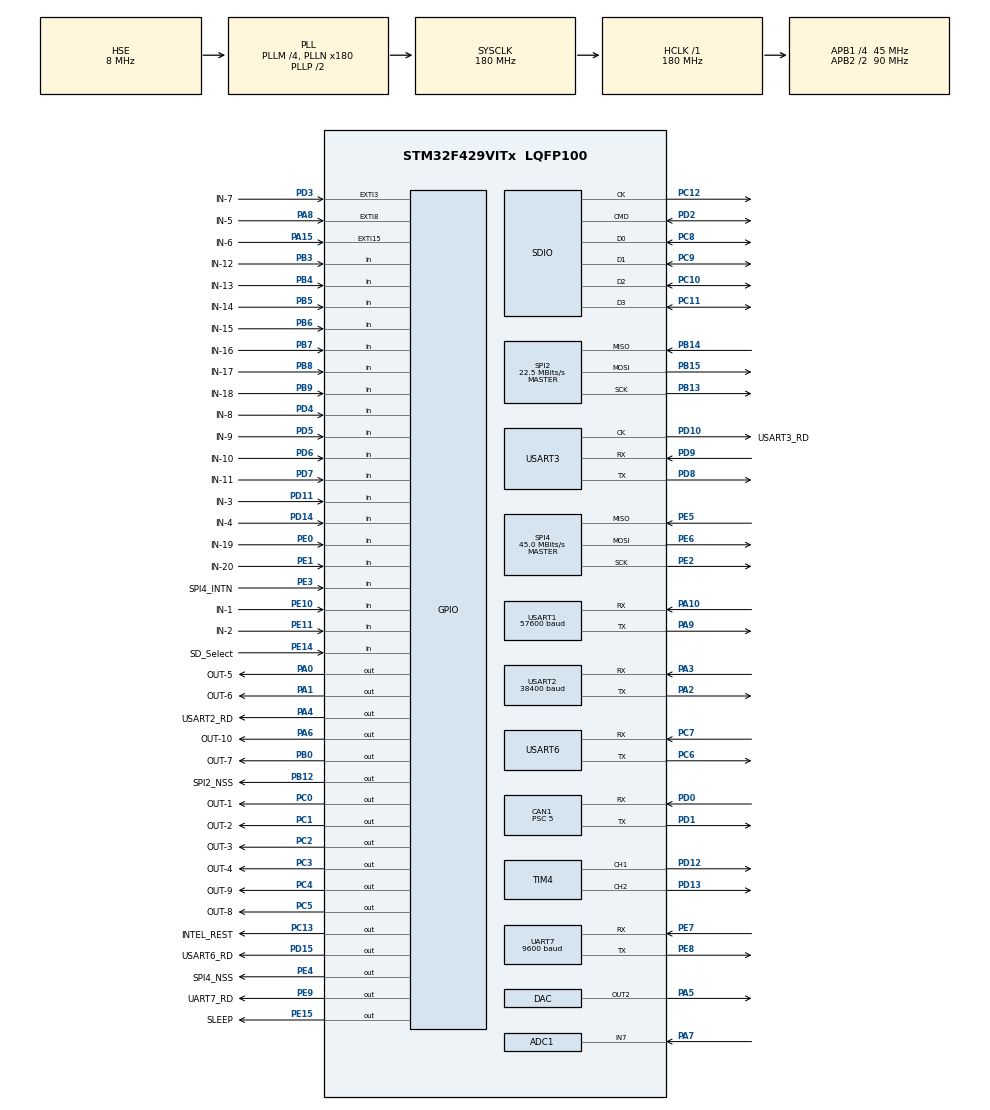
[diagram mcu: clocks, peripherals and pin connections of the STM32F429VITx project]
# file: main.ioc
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ADC1.Channel-0\#ChannelRegularConversion=ADC_CHANNEL_7
ADC1.NbrOfConversionFlag=1
ADC1.Rank-0\#ChannelRegularConversion=1
ADC1.SamplingTime-0\#ChannelRegularConversion=ADC_SAMPLETIME_3CYCLES
ADC1.master=1
CAN1.ABOM=ENABLE
CAN1.AWUM=ENABLE
CAN1.BS1=CAN_BS1_6TQ
CAN1.BS2=CAN_BS2_2TQ
CAN1.CalculateTimeQuantum=111.11111111111111
CAN1.Prescaler=5
Dma.Request0=USART2_RX
Dma.Request1=USART1_RX
Dma.Request2=USART2_TX
Dma.Request3=USART1_TX
Dma.Request4=UART7_RX
Dma.Request5=UART7_TX
Dma.UART7_RX.4.Direction=DMA_PERIPH_TO_MEMORY
Dma.UART7_RX.4.FIFOMode=DMA_FIFOMODE_DISABLE
Dma.UART7_RX.4.Instance=DMA1_Stream3
Dma.UART7_RX.4.MemDataAlignment=DMA_MDATAALIGN_BYTE
Dma.UART7_RX.4.MemInc=DMA_MINC_ENABLE
Dma.UART7_RX.4.Mode=DMA_NORMAL
Dma.UART7_RX.4.PeriphDataAlignment=DMA_PDATAALIGN_BYTE
Dma.UART7_RX.4.PeriphInc=DMA_PINC_DISABLE
Dma.UART7_RX.4.Priority=DMA_PRIORITY_MEDIUM
Dma.UART7_TX.5.Direction=DMA_MEMORY_TO_PERIPH
Dma.UART7_TX.5.FIFOMode=DMA_FIFOMODE_DISABLE
Dma.UART7_TX.5.Instance=DMA1_Stream1
Dma.UART7_TX.5.MemDataAlignment=DMA_MDATAALIGN_BYTE
Dma.UART7_TX.5.MemInc=DMA_MINC_ENABLE
Dma.UART7_TX.5.Mode=DMA_NORMAL
Dma.UART7_TX.5.PeriphDataAlignment=DMA_PDATAALIGN_BYTE
Dma.UART7_TX.5.PeriphInc=DMA_PINC_DISABLE
Dma.UART7_TX.5.Priority=DMA_PRIORITY_MEDIUM
Dma.USART1_RX.1.Direction=DMA_PERIPH_TO_MEMORY
Dma.USART1_RX.1.FIFOMode=DMA_FIFOMODE_DISABLE
Dma.USART1_RX.1.Instance=DMA2_Stream2
Dma.USART1_RX.1.MemDataAlignment=DMA_MDATAALIGN_BYTE
Dma.USART1_RX.1.MemInc=DMA_MINC_ENABLE
Dma.USART1_RX.1.Mode=DMA_CIRCULAR
Dma.USART1_RX.1.PeriphDataAlignment=DMA_PDATAALIGN_BYTE
Dma.USART1_RX.1.PeriphInc=DMA_PINC_DISABLE
Dma.USART1_RX.1.Priority=DMA_PRIORITY_MEDIUM
Dma.USART1_TX.3.Direction=DMA_MEMORY_TO_PERIPH
Dma.USART1_TX.3.FIFOMode=DMA_FIFOMODE_DISABLE
Dma.USART1_TX.3.Instance=DMA2_Stream7
Dma.USART1_TX.3.MemDataAlignment=DMA_MDATAALIGN_BYTE
Dma.USART1_TX.3.MemInc=DMA_MINC_ENABLE
Dma.USART1_TX.3.Mode=DMA_NORMAL
Dma.USART1_TX.3.PeriphDataAlignment=DMA_PDATAALIGN_BYTE
Dma.USART1_TX.3.PeriphInc=DMA_PINC_DISABLE
Dma.USART1_TX.3.Priority=DMA_PRIORITY_MEDIUM
Dma.USART2_RX.0.Direction=DMA_PERIPH_TO_MEMORY
Dma.USART2_RX.0.FIFOMode=DMA_FIFOMODE_DISABLE
Dma.USART2_RX.0.Instance=DMA1_Stream5
Dma.USART2_RX.0.MemDataAlignment=DMA_MDATAALIGN_BYTE
Dma.USART2_RX.0.MemInc=DMA_MINC_ENABLE
Dma.USART2_RX.0.Mode=DMA_NORMAL
Dma.USART2_RX.0.PeriphDataAlignment=DMA_PDATAALIGN_BYTE
Dma.USART2_RX.0.PeriphInc=DMA_PINC_DISABLE
Dma.USART2_RX.0.Priority=DMA_PRIORITY_MEDIUM
Dma.USART2_TX.2.Direction=DMA_MEMORY_TO_PERIPH
Dma.USART2_TX.2.FIFOMode=DMA_FIFOMODE_DISABLE
Dma.USART2_TX.2.Instance=DMA1_Stream6
Dma.USART2_TX.2.MemDataAlignment=DMA_MDATAALIGN_BYTE
Dma.USART2_TX.2.MemInc=DMA_MINC_ENABLE
Dma.USART2_TX.2.Mode=DMA_CIRCULAR
Dma.USART2_TX.2.PeriphDataAlignment=DMA_PDATAALIGN_BYTE
Dma.USART2_TX.2.PeriphInc=DMA_PINC_DISABLE
Dma.USART2_TX.2.Priority=DMA_PRIORITY_MEDIUM
FATFS.BSP.number=1
FATFS0.BSP.STBoard=false
FATFS0.BSP.api=Unknown
FATFS0.BSP.i2caddr=0
FATFS0.BSP.instance=PE14
FATFS0.BSP.ip=GPIO
FATFS0.BSP.mode=Input
FATFS0.BSP.name=Detect_SDIO
FATFS0.BSP.solution=PE14
FREERTOS.INCLUDE_eTaskGetState=1
FREERTOS.INCLUDE_vTaskCleanUpResources=1
FREERTOS.INCLUDE_vTaskDelayUntil=1
FREERTOS.Tasks01=defaultTask,0,128,InitTask,As weak,NULL,Dynamic,NULL,NULL
FREERTOS.configCHECK_FOR_STACK_OVERFLOW=1
FREERTOS.configGENERATE_RUN_TIME_STATS=1
FREERTOS.configTOTAL_HEAP_SIZE=153600
FREERTOS.configUSE_STATS_FORMATTING_FUNCTIONS=1
FREERTOS.configUSE_TICK_HOOK=1
FREERTOS.configUSE_TRACE_FACILITY=1
IWDG.Prescaler=IWDG_PRESCALER_8
Mcu.Family=STM32F4
Mcu.Name=STM32F429VITx
Mcu.Package=LQFP100
NVIC.CAN1_RX0_IRQn=true\:5\:0\:false\:false\:true\:true\:true\:true
NVIC.CAN1_RX1_IRQn=true\:5\:0\:false\:false\:true\:true\:true\:true
NVIC.DMA1_Stream1_IRQn=true\:5\:0\:false\:false\:true\:true\:false\:true
NVIC.DMA1_Stream3_IRQn=true\:5\:0\:false\:false\:true\:true\:false\:true
NVIC.DMA1_Stream5_IRQn=true\:5\:0\:false\:false\:true\:true\:true\:false
NVIC.DMA1_Stream6_IRQn=true\:5\:0\:false\:false\:true\:true\:false\:true
NVIC.DMA2_Stream2_IRQn=true\:5\:0\:false\:false\:true\:true\:false\:true
NVIC.DMA2_Stream7_IRQn=true\:5\:0\:false\:false\:true\:true\:false\:true
NVIC.EXTI15_10_IRQn=true\:5\:0\:false\:false\:true\:true\:true\:true
NVIC.EXTI3_IRQn=true\:5\:0\:false\:false\:true\:true\:true\:true
NVIC.EXTI9_5_IRQn=true\:5\:0\:false\:false\:true\:true\:true\:true
NVIC.PriorityGroup=NVIC_PRIORITYGROUP_4
NVIC.UART7_IRQn=true\:5\:0\:false\:false\:true\:true\:true\:true
NVIC.USART1_IRQn=true\:5\:0\:false\:false\:false\:true\:true\:false
NVIC.USART2_IRQn=true\:5\:0\:false\:false\:true\:true\:true\:true
PA0/WKUP.GPIO_Label=OUT-5
PA0/WKUP.Signal=GPIO_Output
PA1.GPIO_Label=OUT-6
PA1.Signal=GPIO_Output
PA10.Mode=Asynchronous
PA10.Signal=USART1_RX
PA11.Signal=USB_OTG_FS_DM
PA12.Signal=USB_OTG_FS_DP
PA13.GPIO_Label=SWDIO
PA13.Mode=Serial_Wire
PA13.Signal=SYS_JTMS-SWDIO
PA14.GPIO_Label=SWCLK
PA14.Mode=Serial_Wire
PA14.Signal=SYS_JTCK-SWCLK
PA15.GPIO_Label=IN-6
PA15.GPIO_ModeDefaultEXTI=GPIO_MODE_IT_FALLING
PA15.Signal=GPXTI15
PA2.Mode=Asynchronous
PA2.Signal=USART2_TX
PA3.Mode=Asynchronous
PA3.Signal=USART2_RX
PA4.GPIO_Label=USART2_RD
PA4.Signal=GPIO_Output
PA5.Signal=COMP_DAC2_group
PA6.GPIO_Label=OUT-10
PA6.Signal=GPIO_Output
PA7.Signal=ADCx_IN7
PA8.GPIO_Label=IN-5
PA8.Signal=GPXTI8
PA9.Mode=Asynchronous
PA9.Signal=USART1_TX
PB0.GPIO_Label=OUT-7
PB0.Signal=GPIO_Output
PB10.Signal=I2S2_CK
PB11.Signal=I2C2_SDA
PB12.GPIO_Label=SPI2_NSS
PB12.Signal=GPIO_Output
PB13.Mode=Full_Duplex_Master
PB13.Signal=SPI2_SCK
PB14.Mode=Full_Duplex_Master
PB14.Signal=SPI2_MISO
PB15.Mode=Full_Duplex_Master
PB15.Signal=SPI2_MOSI
PB3.GPIO_Label=IN-12
PB3.Signal=GPIO_Input
PB4.GPIO_Label=IN-13
PB4.Signal=GPIO_Input
PB5.GPIO_Label=IN-14
PB5.Signal=GPIO_Input
PB6.GPIO_Label=IN-15
PB6.Signal=GPIO_Input
PB7.GPIO_Label=IN-16
PB7.Signal=GPIO_Input
PB8.GPIO_Label=IN-17
PB8.Signal=GPIO_Input
PB9.GPIO_Label=IN-18
PB9.Signal=GPIO_Input
PC0.GPIO_Label=OUT-1
PC0.Signal=GPIO_Output
PC1.GPIO_Label=OUT-2
PC1.Signal=GPIO_Output
PC10.Mode=SD_4_bits_Wide_bus
PC10.Signal=SDIO_D2
PC11.Mode=SD_4_bits_Wide_bus
PC11.Signal=SDIO_D3
PC12.Mode=SD_4_bits_Wide_bus
PC12.Signal=SDIO_CK
PC13.GPIO_Label=INTEL_REST
PC13.GPIO_PuPd=GPIO_PULLUP
PC13.GPIO_Speed=GPIO_SPEED_FREQ_LOW
PC13.PinState=GPIO_PIN_RESET
PC13.Signal=GPIO_Output
PC14/OSC32_IN.Mode=LSE-External-Oscillator
PC14/OSC32_IN.Signal=RCC_OSC32_IN
PC15/OSC32_OUT.Mode=LSE-External-Oscillator
PC15/OSC32_OUT.Signal=RCC_OSC32_OUT
PC2.GPIO_Label=OUT-3
PC2.Signal=GPIO_Output
PC3.GPIO_Label=OUT-4
PC3.Signal=GPIO_Output
PC4.GPIO_Label=OUT-9
PC4.Signal=GPIO_Output
PC5.GPIO_Label=OUT-8
PC5.Signal=GPIO_Output
PC6.Mode=Asynchronous
PC6.Signal=USART6_TX
PC7.Mode=Asynchronous
PC7.Signal=USART6_RX
PC8.Mode=SD_4_bits_Wide_bus
PC8.Signal=SDIO_D0
PC9.Mode=SD_4_bits_Wide_bus
PC9.Signal=SDIO_D1
PD0.Mode=Master
PD0.Signal=CAN1_RX
PD1.Mode=Master
PD1.Signal=CAN1_TX
PD10.GPIO_Label=USART3_RD
PD10.Mode=Synchronous
PD10.Signal=USART3_CK
PD11.GPIO_Label=IN-3
PD11.Signal=GPIO_Input
PD12.Signal=S_TIM4_CH1
PD13.Signal=S_TIM4_CH2
PD14.GPIO_Label=IN-4
PD14.Signal=GPIO_Input
PD15.GPIO_Label=USART6_RD
PD15.Signal=GPIO_Output
PD2.Mode=SD_4_bits_Wide_bus
PD2.Signal=SDIO_CMD
PD3.GPIO_Label=IN-7
PD3.GPIO_ModeDefaultEXTI=GPIO_MODE_IT_FALLING
PD3.Signal=GPXTI3
PD4.GPIO_Label=IN-8
PD4.Signal=GPIO_Input
PD5.GPIO_Label=IN-9
PD5.Signal=GPIO_Input
PD6.GPIO_Label=IN-10
PD6.Signal=GPIO_Input
PD7.GPIO_Label=IN-11
PD7.Signal=GPIO_Input
PD8.Mode=Synchronous
PD8.Signal=USART3_TX
PD9.Mode=Synchronous
PD9.Signal=USART3_RX
PE0.GPIO_Label=IN-19
PE0.Signal=GPIO_Input
PE1.GPIO_Label=IN-20
PE1.Signal=GPIO_Input
PE10.GPIO_Label=IN-1
PE10.Signal=GPIO_Input
PE11.GPIO_Label=IN-2
PE11.Signal=GPIO_Input
PE14.GPIO_Label=SD_Select
PE14.Signal=GPIO_Input
PE15.GPIO_Label=SLEEP
PE15.Signal=GPIO_Output
PE2.Mode=Full_Duplex_Master
PE2.Signal=SPI4_SCK
PE3.GPIO_Label=SPI4_INTN
PE3.Signal=GPIO_Input
PE4.GPIO_Label=SPI4_NSS
PE4.Signal=GPIO_Output
PE5.Mode=Full_Duplex_Master
PE5.Signal=SPI4_MISO
PE6.Mode=Full_Duplex_Master
PE6.Signal=SPI4_MOSI
PE7.Mode=Asynchronous
PE7.Signal=UART7_RX
PE8.Mode=Asynchronous
PE8.Signal=UART7_TX
PE9.GPIO_Label=UART7_RD
PE9.Signal=GPIO_Output
PH0/OSC_IN.Mode=HSE-External-Oscillator
PH0/OSC_IN.Signal=RCC_OSC_IN
PH1/OSC_OUT.Mode=HSE-External-Oscillator
PH1/OSC_OUT.Signal=RCC_OSC_OUT
ProjectManager.HeapSize=0x200
ProjectManager.StackSize=0x1000
ProjectManager.TargetToolchain=MDK-ARM V5
RCC.48MHZClocksFreq_Value=45000000
RCC.AHBFreq_Value=180000000
RCC.APB1CLKDivider=RCC_HCLK_DIV4
RCC.APB1Freq_Value=45000000
RCC.APB1TimFreq_Value=90000000
RCC.APB2CLKDivider=RCC_HCLK_DIV2
RCC.APB2Freq_Value=90000000
RCC.APB2TimFreq_Value=180000000
RCC.CortexFreq_Value=180000000
RCC.EnbaleCSS=true
RCC.HCLKFreq_Value=180000000
RCC.HSE_VALUE=8000000
RCC.HSI_VALUE=16000000
RCC.PLLM=4
RCC.PLLN=180
RCC.PLLQ=8
RCC.PLLSourceVirtual=RCC_PLLSOURCE_HSE
RCC.SYSCLKFreq_VALUE=180000000
RCC.SYSCLKSource=RCC_SYSCLKSOURCE_PLLCLK
RCC.VCOOutputFreq_Value=360000000
SH.ADCx_IN7.0=ADC1_IN7,IN7
SH.COMP_DAC2_group.0=DAC_OUT2,DAC_OUT2
SH.S_TIM4_CH1.0=TIM4_CH1,PWM Generation1 CH1
SH.S_TIM4_CH2.0=TIM4_CH2,PWM Generation2 CH2
SPI2.BaudRatePrescaler=SPI_BAUDRATEPRESCALER_2
SPI2.CalculateBaudRate=22.5 MBits/s
SPI2.Direction=SPI_DIRECTION_2LINES
SPI2.Mode=SPI_MODE_MASTER
SPI2.VirtualType=VM_MASTER
SPI4.BaudRatePrescaler=SPI_BAUDRATEPRESCALER_2
SPI4.CalculateBaudRate=45.0 MBits/s
SPI4.Direction=SPI_DIRECTION_2LINES
SPI4.Mode=SPI_MODE_MASTER
SPI4.VirtualType=VM_MASTER
TIM3.AutoReloadPreload=TIM_AUTORELOAD_PRELOAD_ENABLE
TIM3.Channel-PWM\ Generation2\ CH2=TIM_CHANNEL_2
TIM3.Period=199
TIM3.Prescaler=799
TIM4.Channel-PWM\ Generation1\ CH1=TIM_CHANNEL_1
TIM4.Channel-PWM\ Generation2\ CH2=TIM_CHANNEL_2
UART7.BaudRate=9600
UART7.VirtualMode=Asynchronous
USART1.BaudRate=57600
USART1.VirtualMode=VM_ASYNC
USART2.BaudRate=38400
USART2.VirtualMode=VM_ASYNC
USART3.VirtualMode=VM_SYNC
USART6.VirtualMode=VM_ASYNC
VP_FATFS_VS_SDIO.Mode=SDIO
VP_FREERTOS_VS_CMSIS_V1.Mode=CMSIS_V1
VP_IWDG_VS_IWDG.Mode=IWDG_Activate
VP_RTC_VS_RTC_Activate.Mode=RTC_Enabled
VP_TIM3_VS_ClockSourceINT.Mode=Internal
VP_TIM4_VS_ClockSourceINT.Mode=Internal
board=custom

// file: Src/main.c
/* USER CODE BEGIN Header */
/**
  ******************************************************************************
  * @file           : main.c
  * @brief          : Main program body
  ******************************************************************************
  * This notice applies to any and all portions of this file
  * that are not between comment pairs USER CODE BEGIN and
  * USER CODE END. Other portions of this file, whether
  * inserted by the user or by software development tools
  * are owned by their respective copyright owners.
  *
  * Copyright (c) 2019 STMicroelectronics International N.V.
  * All rights reserved.
  *
  * Redistribution and use in source and binary forms, with or without
  * modification, are permitted, provided that the following conditions are met:
  *
  * 1. Redistribution of source code must retain the above copyright notice,
  *    this list of conditions and the following disclaimer.
  * 2. Redistributions in binary form must reproduce the above copyright notice,
  *    this list of conditions and the following disclaimer in the documentation
  *    and/or other materials provided with the distribution.
  * 3. Neither the name of STMicroelectronics nor the names of other
  *    contributors to this software may be used to endorse or promote products
  *    derived from this software without specific written permission.
  * 4. This software, including modifications and/or derivative works of this
  *    software, must execute solely and exclusively on microcontroller or
  *    microprocessor devices manufactured by or for STMicroelectronics.
  * 5. Redistribution and use of this software other than as permitted under
  *    this license is void and will automatically terminate your rights under
  *    this license.
  *
  * THIS SOFTWARE IS PROVIDED BY STMICROELECTRONICS AND CONTRIBUTORS "AS IS"
  * AND ANY EXPRESS, IMPLIED OR STATUTORY WARRANTIES, INCLUDING, BUT NOT
  * LIMITED TO, THE IMPLIED WARRANTIES OF MERCHANTABILITY, FITNESS FOR A
  * PARTICULAR PURPOSE AND NON-INFRINGEMENT OF THIRD PARTY INTELLECTUAL PROPERTY
  * RIGHTS ARE DISCLAIMED TO THE FULLEST EXTENT PERMITTED BY LAW. IN NO EVENT
  * SHALL STMICROELECTRONICS OR CONTRIBUTORS BE LIABLE FOR ANY DIRECT, INDIRECT,
  * INCIDENTAL, SPECIAL, EXEMPLARY, OR CONSEQUENTIAL DAMAGES (INCLUDING, BUT NOT
  * LIMITED TO, PROCUREMENT OF SUBSTITUTE GOODS OR SERVICES; LOSS OF USE, DATA,
  * OR PROFITS; OR BUSINESS INTERRUPTION) HOWEVER CAUSED AND ON ANY THEORY OF
  * LIABILITY, WHETHER IN CONTRACT, STRICT LIABILITY, OR TORT (INCLUDING
  * NEGLIGENCE OR OTHERWISE) ARISING IN ANY WAY OUT OF THE USE OF THIS SOFTWARE,
  * EVEN IF ADVISED OF THE POSSIBILITY OF SUCH DAMAGE.
  *
  ******************************************************************************
  */
/* USER CODE END Header */

#include "main.h"
#include "cmsis_os.h"
#include "adc.h"
#include "can.h"
#include "dac.h"
#include "dma.h"
#include "fatfs.h"
#include "iwdg.h"
#include "rtc.h"
#include "sdio.h"
#include "spi.h"
#include "tim.h"
#include "usart.h"
#include "gpio.h"

/* USER CODE BEGIN PV */
/* Private variables ---------------------------------------------------------*/

/* USER CODE END PV */

void SystemClock_Config(void);
void MX_FREERTOS_Init(void);
/* USER CODE BEGIN PFP */
/* Private function prototypes -----------------------------------------------*/

/* USER CODE END PFP */

int main(void)
{

  /* MCU Configuration--------------------------------------------------------*/

  /* Reset of all peripherals, Initializes the Flash interface and the Systick. */
  HAL_Init();

  /* Configure the system clock */
  SystemClock_Config();

  /* Initialize all configured peripherals */
  MX_GPIO_Init();
  MX_DMA_Init();
  MX_USART3_Init();
  MX_SPI4_Init();
  MX_USART1_UART_Init();
  MX_USART6_UART_Init();
  MX_TIM4_Init();
  MX_SPI2_Init();
  MX_UART7_Init();
  MX_TIM3_Init();
  MX_USART2_UART_Init();
  MX_SDIO_SD_Init();
  MX_CAN1_Init();
  MX_ADC1_Init();
  MX_DAC_Init();
 // MX_IWDG_Init();
  MX_RTC_Init();

  /* Call init function for freertos objects (in freertos.c) */
  MX_FREERTOS_Init();

  /* Start scheduler */
  osKernelStart();

  /* We should never get here as control is now taken by the scheduler */

  /* Infinite loop */
  while (1)
  {

  }
}

void SystemClock_Config(void)
{
  RCC_OscInitTypeDef RCC_OscInitStruct = {0};
  RCC_ClkInitTypeDef RCC_ClkInitStruct = {0};
  RCC_PeriphCLKInitTypeDef PeriphClkInitStruct = {0};

  /** Configure the main internal regulator output voltage
  */
  __HAL_RCC_PWR_CLK_ENABLE();
  __HAL_PWR_VOLTAGESCALING_CONFIG(PWR_REGULATOR_VOLTAGE_SCALE1);
  /** Initializes the CPU, AHB and APB busses clocks
  */
  RCC_OscInitStruct.OscillatorType = RCC_OSCILLATORTYPE_LSI|RCC_OSCILLATORTYPE_HSE;
  RCC_OscInitStruct.HSEState = RCC_HSE_ON;
  RCC_OscInitStruct.LSIState = RCC_LSI_ON;
  RCC_OscInitStruct.PLL.PLLState = RCC_PLL_ON;
  RCC_OscInitStruct.PLL.PLLSource = RCC_PLLSOURCE_HSE;
  RCC_OscInitStruct.PLL.PLLM = 4;
  RCC_OscInitStruct.PLL.PLLN = 180;
  RCC_OscInitStruct.PLL.PLLP = RCC_PLLP_DIV2;
  RCC_OscInitStruct.PLL.PLLQ = 8;
  if (HAL_RCC_OscConfig(&RCC_OscInitStruct) != HAL_OK)
  {
    Error_Handler();
  }
  /** Activate the Over-Drive mode
  */
  if (HAL_PWREx_EnableOverDrive() != HAL_OK)
  {
    Error_Handler();
  }
  /** Initializes the CPU, AHB and APB busses clocks
  */
  RCC_ClkInitStruct.ClockType = RCC_CLOCKTYPE_HCLK|RCC_CLOCKTYPE_SYSCLK
                              |RCC_CLOCKTYPE_PCLK1|RCC_CLOCKTYPE_PCLK2;
  RCC_ClkInitStruct.SYSCLKSource = RCC_SYSCLKSOURCE_PLLCLK;
  RCC_ClkInitStruct.AHBCLKDivider = RCC_SYSCLK_DIV1;
  RCC_ClkInitStruct.APB1CLKDivider = RCC_HCLK_DIV4;
  RCC_ClkInitStruct.APB2CLKDivider = RCC_HCLK_DIV2;

  if (HAL_RCC_ClockConfig(&RCC_ClkInitStruct, FLASH_LATENCY_5) != HAL_OK)
  {
    Error_Handler();
  }
  PeriphClkInitStruct.PeriphClockSelection = RCC_PERIPHCLK_RTC;
  PeriphClkInitStruct.RTCClockSelection = RCC_RTCCLKSOURCE_LSI;
  if (HAL_RCCEx_PeriphCLKConfig(&PeriphClkInitStruct) != HAL_OK)
  {
    Error_Handler();
  }
  /** Enables the Clock Security System
  */
  HAL_RCC_EnableCSS();
}

void Error_Handler(void)
{
  /* USER CODE BEGIN Error_Handler_Debug */
  /* User can add his own implementation to report the HAL error return state */
  while(1)
  {
      HAL_GPIO_WritePin( OUT_5_GPIO_Port, OUT_5_Pin, GPIO_PIN_RESET);
  }
  /* USER CODE END Error_Handler_Debug */
}

/************************ (C) COPYRIGHT STMicroelectronics *****END OF FILE****/

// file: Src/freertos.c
/* USER CODE BEGIN Header */
/**
  ******************************************************************************
  * File Name          : freertos.c
  * Description        : Code for freertos applications
  ******************************************************************************
  * This notice applies to any and all portions of this file
  * that are not between comment pairs USER CODE BEGIN and
  * USER CODE END. Other portions of this file, whether
  * inserted by the user or by software development tools
  * are owned by their respective copyright owners.
  *
  * Copyright (c) 2019 STMicroelectronics International N.V.
  * All rights reserved.
  *
  * Redistribution and use in source and binary forms, with or without
  * modification, are permitted, provided that the following conditions are met:
  *
  * 1. Redistribution of source code must retain the above copyright notice,
  *    this list of conditions and the following disclaimer.
  * 2. Redistributions in binary form must reproduce the above copyright notice,
  *    this list of conditions and the following disclaimer in the documentation
  *    and/or other materials provided with the distribution.
  * 3. Neither the name of STMicroelectronics nor the names of other
  *    contributors to this software may be used to endorse or promote products
  *    derived from this software without specific written permission.
  * 4. This software, including modifications and/or derivative works of this
  *    software, must execute solely and exclusively on microcontroller or
  *    microprocessor devices manufactured by or for STMicroelectronics.
  * 5. Redistribution and use of this software other than as permitted under
  *    this license is void and will automatically terminate your rights under
  *    this license.
  *
  * THIS SOFTWARE IS PROVIDED BY STMICROELECTRONICS AND CONTRIBUTORS "AS IS"
  * AND ANY EXPRESS, IMPLIED OR STATUTORY WARRANTIES, INCLUDING, BUT NOT
  * LIMITED TO, THE IMPLIED WARRANTIES OF MERCHANTABILITY, FITNESS FOR A
  * PARTICULAR PURPOSE AND NON-INFRINGEMENT OF THIRD PARTY INTELLECTUAL PROPERTY
  * RIGHTS ARE DISCLAIMED TO THE FULLEST EXTENT PERMITTED BY LAW. IN NO EVENT
  * SHALL STMICROELECTRONICS OR CONTRIBUTORS BE LIABLE FOR ANY DIRECT, INDIRECT,
  * INCIDENTAL, SPECIAL, EXEMPLARY, OR CONSEQUENTIAL DAMAGES (INCLUDING, BUT NOT
  * LIMITED TO, PROCUREMENT OF SUBSTITUTE GOODS OR SERVICES; LOSS OF USE, DATA,
  * OR PROFITS; OR BUSINESS INTERRUPTION) HOWEVER CAUSED AND ON ANY THEORY OF
  * LIABILITY, WHETHER IN CONTRACT, STRICT LIABILITY, OR TORT (INCLUDING
  * NEGLIGENCE OR OTHERWISE) ARISING IN ANY WAY OUT OF THE USE OF THIS SOFTWARE,
  * EVEN IF ADVISED OF THE POSSIBILITY OF SUCH DAMAGE.
  *
  ******************************************************************************
  */
/* USER CODE END Header */

#include "FreeRTOS.h"
#include "task.h"
#include "main.h"
#include "cmsis_os.h"

osThreadId defaultTaskHandle;

void InitTask(void const * argument);

extern void MX_FATFS_Init(void);
void MX_FREERTOS_Init(void); /* (MISRA C 2004 rule 8.1) */

/* GetIdleTaskMemory prototype (linked to static allocation support) */
void vApplicationGetIdleTaskMemory( StaticTask_t **ppxIdleTaskTCBBuffer, StackType_t **ppxIdleTaskStackBuffer, uint32_t *pulIdleTaskStackSize );

/* Hook prototypes */
void configureTimerForRunTimeStats(void);
unsigned long getRunTimeCounterValue(void);
void vApplicationTickHook(void);
void vApplicationStackOverflowHook(xTaskHandle xTask, signed char *pcTaskName);

/* USER CODE BEGIN 1 */
/* Functions needed when configGENERATE_RUN_TIME_STATS is on */
__weak void configureTimerForRunTimeStats(void)
{

}

__weak unsigned long getRunTimeCounterValue(void)
{
return 0;
}
/* USER CODE END 1 */

/* USER CODE BEGIN 3 */
__weak void vApplicationTickHook( void )
{
   /* This function will be called by each tick interrupt if
   configUSE_TICK_HOOK is set to 1 in FreeRTOSConfig.h. User code can be
   added here, but the tick hook is called from an interrupt context, so
   code must not attempt to block, and only the interrupt safe FreeRTOS API
   functions can be used (those that end in FromISR()). */
}
/* USER CODE END 3 */

/* USER CODE BEGIN 4 */
__weak void vApplicationStackOverflowHook(xTaskHandle xTask, signed char *pcTaskName)
{
   /* Run time stack overflow checking is performed if
   configCHECK_FOR_STACK_OVERFLOW is defined to 1 or 2. This hook function is
   called if a stack overflow is detected. */
}
/* USER CODE END 4 */

/* USER CODE BEGIN GET_IDLE_TASK_MEMORY */
static StaticTask_t xIdleTaskTCBBuffer;
static StackType_t xIdleStack[configMINIMAL_STACK_SIZE];

void vApplicationGetIdleTaskMemory( StaticTask_t **ppxIdleTaskTCBBuffer, StackType_t **ppxIdleTaskStackBuffer, uint32_t *pulIdleTaskStackSize )
{
  *ppxIdleTaskTCBBuffer = &xIdleTaskTCBBuffer;
  *ppxIdleTaskStackBuffer = &xIdleStack[0];
  *pulIdleTaskStackSize = configMINIMAL_STACK_SIZE;
  /* place for user code */
}
/* USER CODE END GET_IDLE_TASK_MEMORY */

void MX_FREERTOS_Init(void) {

  /* Create the thread(s) */
  /* definition and creation of defaultTask */
  osThreadDef(defaultTask, InitTask, osPriorityNormal, 0, 128);
  defaultTaskHandle = osThreadCreate(osThread(defaultTask), NULL);

}

__weak void InitTask(void const * argument)
{
  /* init code for FATFS */
  MX_FATFS_Init();
  for(;;)
  {
    osDelay(1);
  }
}

/************************ (C) COPYRIGHT STMicroelectronics *****END OF FILE****/
